# G32F031 register map
File version: 1.0
CPU: CM0PLUS r0p1, little endian, no MPU, no FPU, 2 interrupt priority bits
Registers are 32-bit, read-write, reset 0x0 unless marked. A register's access mark holds for its fields unless they carry their own. Offsets are from the block's base; [hi:lo] are bit positions; {n}, {i} and the like mark numbered series.

## SCU — System Control Unit
Base 0x40000400
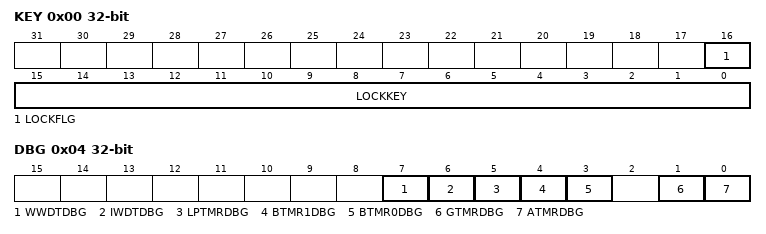
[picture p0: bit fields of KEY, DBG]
0x00 KEY access per field — Read-Write Protection Register
  [16] LOCKFLG ro — Lock flag
  [15:0] LOCKKEY wo — Counter enable
0x04 DBG — System DBG Control Register
  [7] WWDTDBG — In DEBUG mode, WWDT counting method
  [6] IWDTDBG — In DEBUG mode, IWDT counting method
  [5] LPTMRDBG — In DEBUG mode, LPTMR counting method
  [4] BTMR1DBG — In DEBUG mode, BTMR1 counting method
  [3] BTMR0DBG — In DEBUG mode, BTMR0 counting method
  [1] GTMRDBG — In DEBUG mode, GTMR counting method
  [0] ATMRDBG — In DEBUG mode, ATMR counting method

## EINT — External interrupt/event controller
Base 0x40000800
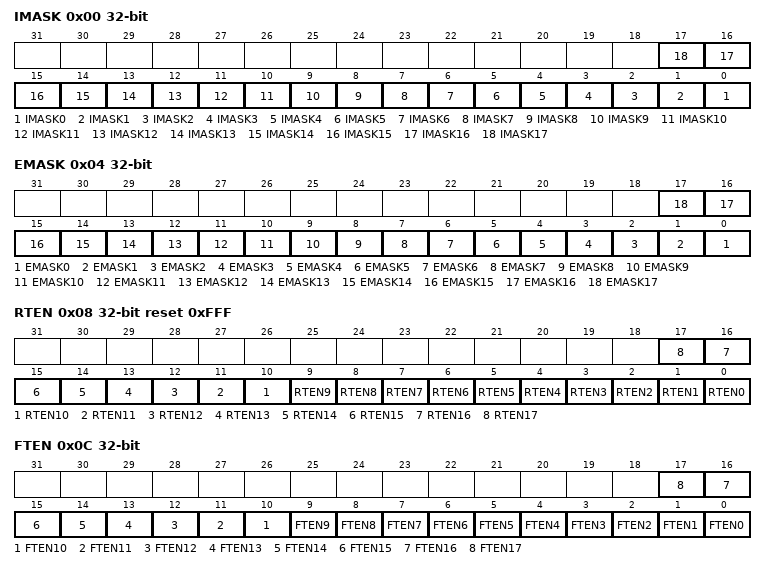
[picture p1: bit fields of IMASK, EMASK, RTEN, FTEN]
0x00 IMASK
  [n] IMASK{n} (n=0..17) — /
0x04 EMASK
  [n] EMASK{n} (n=0..17) — /
0x08 RTEN reset 0xFFF
  [n] RTEN{n} (n=0..17) — /
0x0C FTEN
  [n] FTEN{n} (n=0..17) — /
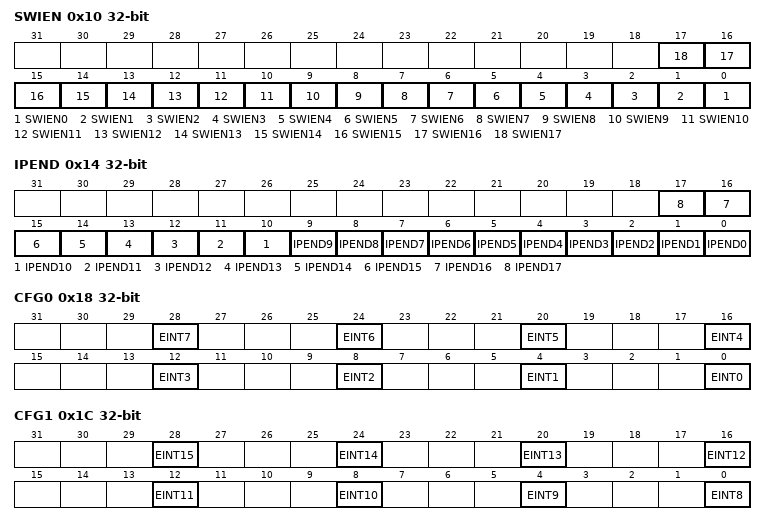
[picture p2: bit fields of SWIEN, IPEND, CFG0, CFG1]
0x10 SWIEN
  [n] SWIEN{n} (n=0..17) — /
0x14 IPEND
  [n] IPEND{n} (n=0..17) — /
0x18 CFG0
  [4n] EINT{n} (n=0..7) — /
0x1C CFG1
  [4n-32] EINT{n} (n=8..15) — /

## BTMR0 — Base timer
Base 0x40001800
Same registers: BTMR1 0x40001C00
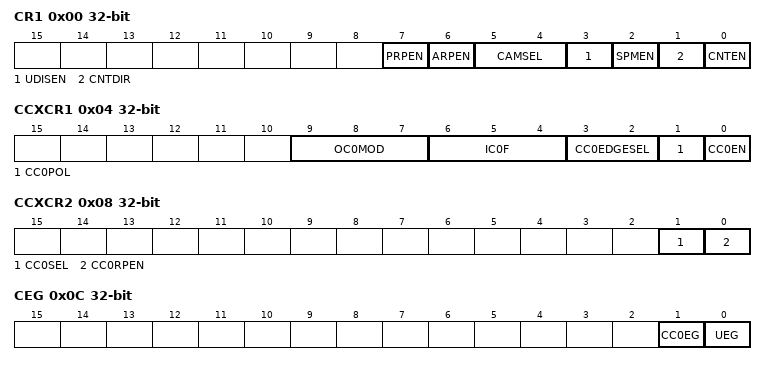
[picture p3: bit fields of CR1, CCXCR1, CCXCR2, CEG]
0x00 CR1 — control register 1
  [7] PRPEN — PSC preload enable
  [6] ARPEN — Auto-reload Preload Enable
  [5:4] CAMSEL — Choose center alignment mode
  [3] UDISEN — Update Disable
  [2] SPMEN — Single Pulse Mode Enable
  [1] CNTDIR — Counter Direction
  [0] CNTEN — BTMR enable
0x04 CCXCR1 — channel control register 1
  [9:7] OC0MOD — Output Compare Channel0 Mode Configure
  [6:4] IC0F — Input filter coefficients (based on timer clock)
  [3:2] CC0EDGESEL — When in input mode: capture the active edge
  [1] CC0POL — Capture/Compare Channel1 Output Polarity Configure
  [0] CC0EN — Capture/compare enable
0x08 CCXCR2 — channel control register 2
  [1] CC0SEL — Channel 0 Input/Output Selection
  [0] CC0RPEN — CCR0 register auto-reload buffer enable
0x0C CEG wo — event generation register
  [1] CC0EG — Capture/compare 0 generation
  [0] UEG — Update generation
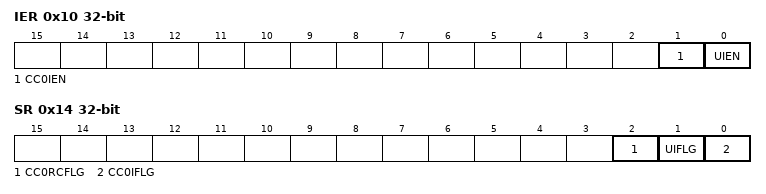
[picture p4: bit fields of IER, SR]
0x10 IER — interrupt enable register
  [1] CC0IEN — Capture/compare 0 interrupt enable
  [0] UIEN — Update interrupt enable
0x14 SR — status register
  [2] CC0RCFLG — Captuer/Compare Channel0 Repetition Capture Flag
  [1] UIFLG — Update interrupt flag
  [0] CC0IFLG — Capture/compare 0 interrupt flag
0x18 CNT — counter
  [15:0] CNT — Counter Value
0x1C PSC — prescaler
  [15:0] PSC — Prescaler value
0x20 AUTORLD reset 0xFFFF — auto-reload register
  [15:0] AUTORLD — Auto Reload Value
0x24 CC0 — capture/compare register 0
  [15:0] CC0 — Capture/Compare 0 value

## LPTMR — Low-power timer
Base 0x40002000
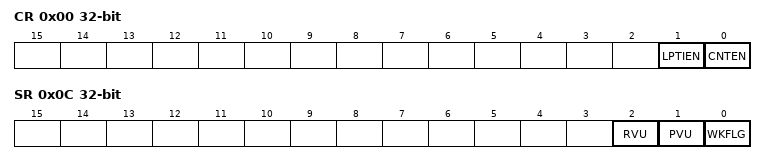
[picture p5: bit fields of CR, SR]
0x00 CR — Control register
  [1] LPTIEN — Module interrupt enable
  [0] CNTEN — Module enablement
0x04 PSC — Prescaler register
  [15:0] PSC — Prescaler divider
0x08 WKVAL reset 0xFFFF — Wakeup Value register
  [15:0] WKVAL — Awakening Value
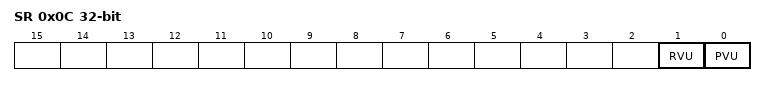
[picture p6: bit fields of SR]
0x0C SR ro — Status register
  [2] RVU — Reload value update indication, automatically reset by hardware after update.
  [1] PVU — PS value update indicator, hardware automatically resets after update.
  [0] WKFLG — Status Register, read SR register clear.
0x10 CNT ro — Counter register
  [15:0] CNT — Counter Value

## IWDT — Independent watchdog
Base 0x40002800
0x00 KEY wo
  [15:0] KEY — Key value (write only, read 0000h)
0x04 PSC — Prescaler register
  [2:0] PSC — Prescaler divider
0x08 RL reset 0xFFF — Reload register
  [11:0] RL — Watchdog counter reload value
0x0C SR ro — Status register
  [1] RVU — Watchdog prescaler value update
  [0] PVU — Watchdog counter reload value update

## WWDT — Window watchdog
Base 0x40002C00
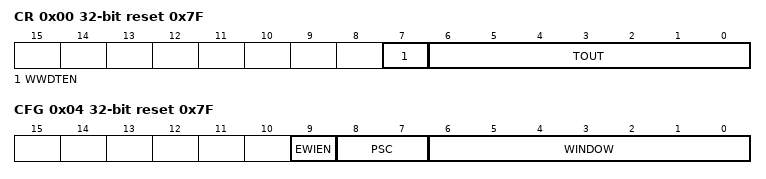
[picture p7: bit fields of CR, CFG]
0x00 CR reset 0x7F — Control register
  [7] WWDTEN — Activation bit
  [6:0] TOUT — 7-bit counter (MSB to LSB)
0x04 CFG reset 0x7F — Configuration register
  [9] EWIEN — Early wakeup interrupt
  [8:7] PSC — Timer Base Prescaler Factor Configure
  [6:0] WINDOW — 7-bit window value
0x08 SR — Status register
  [0] EWIFLG — Early wakeup interrupt flag
